# ZB32L030 register map
Vendor: ZBit.; Series: ZB32L03X; File version: 1.0
CPU: CM0+ r1p0, little endian, no MPU, no FPU, VTOR, 2 interrupt priority bits
Registers are 32-bit, read-write, reset 0x0 unless marked. A register's access mark holds for its fields unless they carry their own. Offsets are from the block's base; [hi:lo] are bit positions; {n}, {i} and the like mark numbered series.

## ADC
Base 0x40002C00
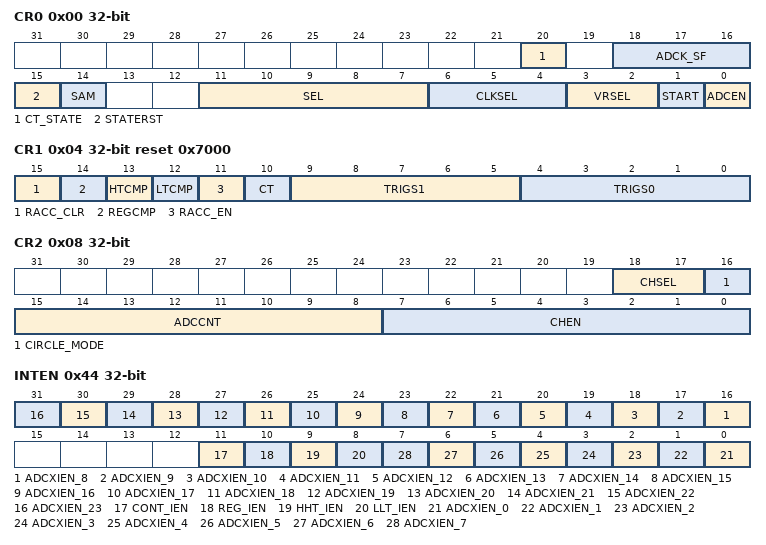
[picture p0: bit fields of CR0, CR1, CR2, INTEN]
0x00 CR0 — ADC Config Register 0
  [20] CT_STATE ro — ADC Continue Convert Status Control
  [18:16] ADCK_SF — ADC clock shift
    0=NO_SHIFT (no shift with SYSCLK); 1=4NS_SHIFT (shift 4ns with SYSCLK); 2=8NS_SHIFT (shift 8ns with SYSCLK); 3=12NS_SHIFT (shift 12ns with SYSCLK); 4=NO_SHIFT_NEDGE (no shift with SYSCLK negative edge); 5=4NS_SHIFT_NEDGE (shift 4ns with SYSCLK negative edge); 6=8NS_SHIFT_NEDGE (shift 8ns with SYSCLK negative edge); 7=12NS_SHIFT_NEDGE (shift 12ns with SYSCLK negative edge)
  [15] STATERST — ADC Continue Convert Status Control
  [14] SAM — ADC Sample Circle Select
  [11:7] SEL — ADC Channel Select
    {v}=AIN{v} (Analog Input channel) (v=0..23)
  [6:4] CLKSEL — ADC Clock Select
    0=PCLK_DIV1 (PCLK dev 1); 1=PCLK_DIV2 (PCLK dev 2); 2=PCLK_DIV4 (PCLK dev 4); 3=PCLK_DIV8 (PCLK dev 8); 4=PCLK_DIV16 (PCLK dev 16); 5=PCLK_DIV32 (PCLK dev 132); 6=PCLK_DIV64 (PCLK dev 64); 7=PCLK_DIV128 (PCLK dev 128)
  [3:2] VRSEL — ADC Vref Select
    0=AVDD (select AVDD); 2=EXT_VREF (select external Vref (PB1)); 3=VCAP (VCAP (2.5V))
  [1] START — Start Control
  [0] ADCEN — ADC Enable
0x04 CR1 reset 0x7000 — ADC Config Register 1
  [15] RACC_CLR — Convect Result register Clear
  [14] REGCMP — Area Compare Control
  [13] HTCMP — High threshold Compare Control
  [12] LTCMP — Low threshold Compare Control
  [11] RACC_EN — Convect Result Auto ADD
  [10] CT — Convect mode Select
  [9:5] TRIGS1 — ADC Convect Auto Triger 1
  [4:0] TRIGS0 — ADC Convect Auto Triger 0
0x08 CR2 — ADC Config Register2
  [18:17] CHSEL — Select Group Channel
    0=AIN7_0 (Group Channel AIN7 ~ 0); 1=AIN15_8 (Group Channel AIN15 ~ 8); 2=AIN23_16 (Group Channel AIN23 ~ 16)
  [16] CIRCLE_MODE — ADC Convect Rounte Mode Select
  [15:8] ADCCNT — ADC Continue Convect Times Config
  [7:0] CHEN — ADC Continue Convect Channel 0 ~ 7 Enable
    1=CH_0 (Channel 0); 2=CH_1 (Channel 1); 4=CH_2 (Channel 2); 8=CH_3 (Channel 3); 16=CH_4 (Channel 4); 32=CH_5 (Channel 5); 64=CH_6 (Channel 6); 128=CH_7 (Channel 7)
0x0C RESULT0 — Channel 0 Result Register
  [11:0] RESULT0 ro — ADC Channel 0 Result
0x10 RESULT1 — Channel 1 Result Register
  [11:0] RESULT1 ro — Channel 1 Result
0x14 RESULT2 — Channel 2 Result Register
  [11:0] RESULT2 ro — Channel 2 Result
0x18 RESULT3 — Channel 3 Result Register
  [11:0] RESULT3 ro — ADC Channel 3 Result
{0xC+4i} RESULT{i} (i=4..7) — Channel {i} Result Register
  [11:0] RESULT{i} ro — Channel {i} Result
0x2C RESULT — Channel Result Register
  [11:0] RESULT ro
0x30 RESULT_ACC — Channel Result accumulate
  [19:0] RESUL_ACC ro — Convect Result Compare High Therashold
0x34 HT reset 0xFFF — Compare High Threshold
  [11:0] HT — ADC Convect Result Compare High threshold
0x38 LT — Compare Low Threshold
  [11:0] LT — Convect Result Compare Low Threshold
0x44 INTEN — Interrupt Enable Register
  [n+8] ADCXIEN_{n} (n=8..23) — ADC Channel {n} Interrupt Mask Config
  [11] CONT_IEN — ADC
  [10] REG_IEN — ADC
  [9] HHT_IEN — HHT
  [8] LLT_IEN — ADC Convect Result
  [n] ADCXIEN_{n} (n=0..7) — ADC Channel {n} Interrupt Mask Config
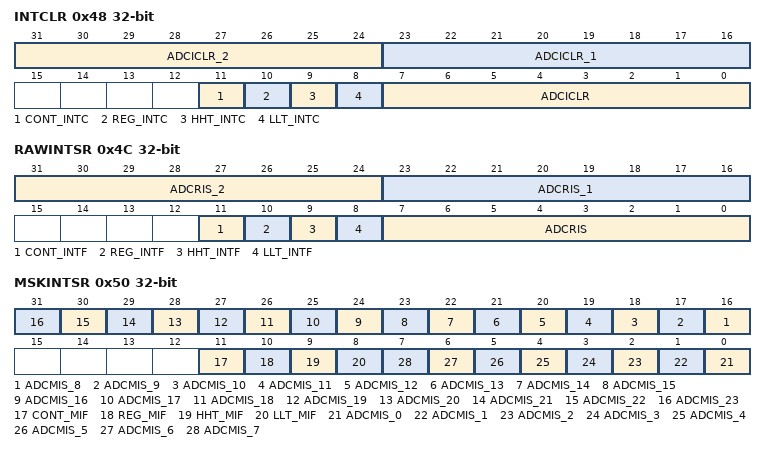
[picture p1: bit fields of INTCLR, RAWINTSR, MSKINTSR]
0x48 INTCLR — Interrupt Clear Register
  [31:24] ADCICLR_2 wo — clear interrupt status (AIN23 ~ AIN16)
  [23:16] ADCICLR_1 wo — clear interrupt status (AIN15 ~ AIN8)
  [11] CONT_INTC wo — clear interrupt status
  [10] REG_INTC wo — clear interrupt status
  [9] HHT_INTC wo — clear interrupt status
  [8] LLT_INTC wo — clear interrupt status
  [7:0] ADCICLR wo — clear interrupt status
0x4C RAWINTSR — Interrupt Status Register before mask
  [31:24] ADCRIS_2 ro — Interrupt Status (AIN16~ AIN23)
  [23:16] ADCRIS_1 ro — Interrupt Status (AIN15~ AIN8)
  [11] CONT_INTF ro — CON
  [10] REG_INTF ro — REG
  [9] HHT_INTF ro — HHT
  [8] LLT_INTF ro — LLT
  [7:0] ADCRIS ro — Interrupt Status (AIN7~ AIN0)
0x50 MSKINTSR — Interrupt Status Register Behind mask
  [n+8] ADCMIS_{n} ro (n=8..23) — Interrupt Status AIN{n}
  [11] CONT_MIF ro — Interrupt Status
  [10] REG_MIF ro — Interrupt Status
  [9] HHT_MIF ro — Interrupt Status
  [8] LLT_MIF ro — Interrupt Status
  [n] ADCMIS_{n} ro (n=0..7) — Interrupt Status AIN{n}
